# CH32F20xxx register map
Vendor: WCH Ltd.; File version: 1.1
Registers are 32-bit, read-write, reset 0x0 unless marked. A register's access mark holds for its fields unless they carry their own. Offsets are from the block's base; [hi:lo] are bit positions.

## ETHERNET_PTP — Ethernet: Precision time protocol
Base 0x40028700
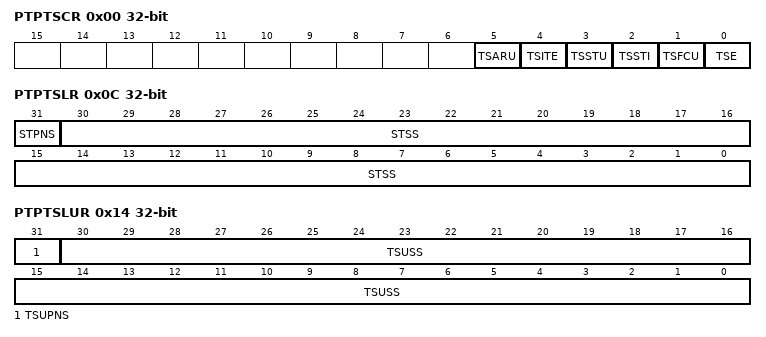
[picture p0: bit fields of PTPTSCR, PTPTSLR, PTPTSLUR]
0x00 PTPTSCR — Ethernet PTP time stamp control register (ETH_PTPTSCR)
  [5] TSARU — Time stamp addend register update
  [4] TSITE — Time stamp interrupt trigger enable
  [3] TSSTU — Time stamp system time update
  [2] TSSTI — Time stamp system time initialize
  [1] TSFCU — Time stamp fine or coarse update
  [0] TSE — Time stamp enable
0x04 PTPSSIR — Ethernet PTP subsecond increment register
  [7:0] STSSI — System time subsecond increment
0x08 PTPTSHR ro — Ethernet PTP time stamp high register
  [31:0] STS — System time second
0x0C PTPTSLR ro — Ethernet PTP time stamp low register (ETH_PTPTSLR)
  [31] STPNS — System time positive or negative sign
  [30:0] STSS — System time subseconds
0x10 PTPTSHUR — Ethernet PTP time stamp high update register
  [31:0] TSUS — Time stamp update second
0x14 PTPTSLUR — Ethernet PTP time stamp low update register (ETH_PTPTSLUR)
  [31] TSUPNS — Time stamp update positive or negative sign
  [30:0] TSUSS — Time stamp update subseconds
0x18 PTPTSAR — Ethernet PTP time stamp addend register
  [31:0] TSA — Time stamp addend
0x1C PTPTTHR — Ethernet PTP target time high register
  [31:0] TTSH — Target time stamp high
0x20 PTPTTLR — Ethernet PTP target time low register
  [31:0] TTSL — Target time stamp low

## FSMC — Flexible static memory controller
Base 0xA0000000
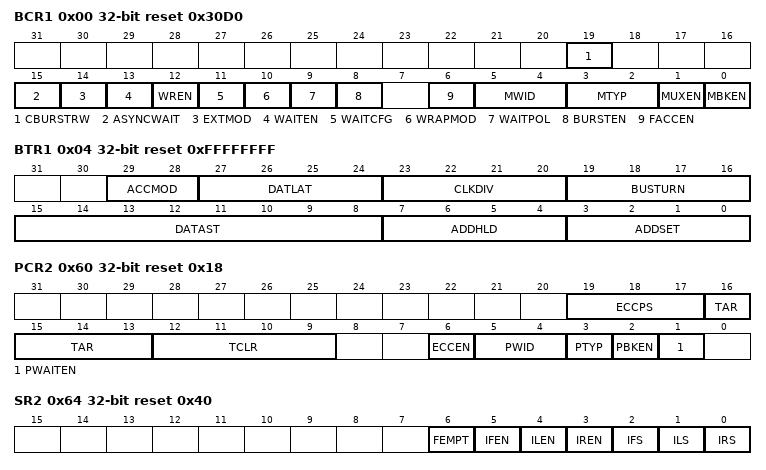
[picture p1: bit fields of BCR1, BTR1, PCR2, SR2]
0x00 BCR1 reset 0x30D0 — SRAM/NOR-Flash chip-select control register 1
  [19] CBURSTRW — Write burst enable
  [15] ASYNCWAIT — Wait signal during asynchronous transfers
  [14] EXTMOD — Extended mode enable
  [13] WAITEN — Wait enable bit
  [12] WREN — Write enable bit
  [11] WAITCFG — Wait timing configuration
  [10] WRAPMOD — Wrapped burst mode support
  [9] WAITPOL — Wait signal polarity bit
  [8] BURSTEN — Burst enable bit
  [6] FACCEN — Flash access enable
  [5:4] MWID — Memory databus width
  [3:2] MTYP — Memory type
  [1] MUXEN — Address/data multiplexing enable bit
  [0] MBKEN — Memory bank enable bit
0x04 BTR1 reset 0xFFFFFFFF — SRAM/NOR-Flash chip-select timing register 1
  [29:28] ACCMOD — Access mode
  [27:24] DATLAT — Data latency for synchronous NOR Flash memory
  [23:20] CLKDIV — Clock divide ratio (for FSMC_CLK signal)
  [19:16] BUSTURN — Bus turnaround phase duration
  [15:8] DATAST — Data-phase duration
  [7:4] ADDHLD — Address-hold phase duration
  [3:0] ADDSET — Address setup phase duration
0x60 PCR2 reset 0x18 — PC Card/NAND Flash control register 2
  [19:17] ECCPS — ECC page size
  [16:13] TAR — ALE to RE delay
  [12:9] TCLR — CLE to RE delay
  [6] ECCEN — ECC computation logic enable bit
  [5:4] PWID — Databus width
  [3] PTYP — Memory type
  [2] PBKEN — PC Card/NAND Flash memory bank enable bit
  [1] PWAITEN — Wait feature enable bit
0x64 SR2 access per field reset 0x40 — FIFO status and interrupt register 2
  [6] FEMPT ro — FIFO empty
  [5] IFEN rw — Interrupt falling edge detection enable bit
  [4] ILEN rw — Interrupt high-level detection enable bit
  [3] IREN rw — Interrupt rising edge detection enable bit
  [2] IFS rw — Interrupt falling edge status
  [1] ILS rw — Interrupt high-level status
  [0] IRS rw — Interrupt rising edge status
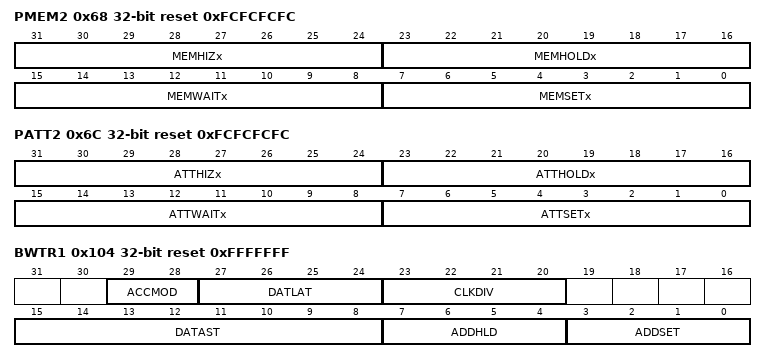
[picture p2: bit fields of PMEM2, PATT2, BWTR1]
0x68 PMEM2 reset 0xFCFCFCFC — Common memory space timing register 2
  [31:24] MEMHIZx — Common memory x databus HiZ time
  [23:16] MEMHOLDx — Common memory x hold time
  [15:8] MEMWAITx — Common memory x wait time
  [7:0] MEMSETx — Common memory x setup time
0x6C PATT2 reset 0xFCFCFCFC — Attribute memory space timing register 2
  [31:24] ATTHIZx — Attribute memory x databus HiZ time
  [23:16] ATTHOLDx — Attribute memory x hold time
  [15:8] ATTWAITx — Attribute memory x wait time
  [7:0] ATTSETx — Attribute memory x setup time
0x74 ECCR2 ro — ECC result register 2
  [31:0] ECCx — ECC result
0x104 BWTR1 reset 0xFFFFFFF — SRAM/NOR-Flash write timing registers 1
  [29:28] ACCMOD — Access mode
  [27:24] DATLAT — Data latency for synchronous NOR Flash memory
  [23:20] CLKDIV — Clock divide ratio (for FSMC_CLK signal)
  [15:8] DATAST — Data-phase duration
  [7:4] ADDHLD — Address-hold phase duration
  [3:0] ADDSET — Address setup phase duration
